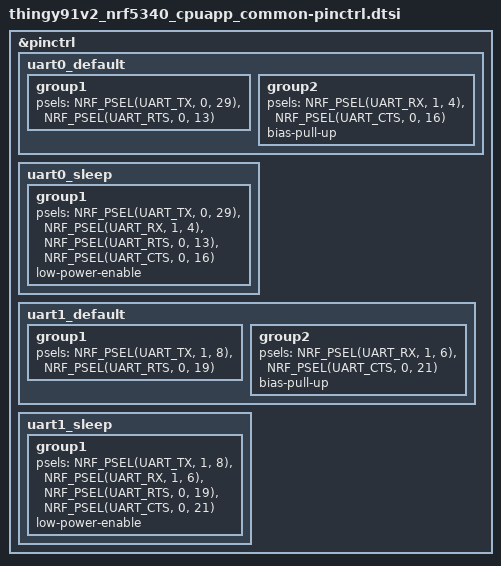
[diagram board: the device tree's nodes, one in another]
/*
 * Copyright (c) 2023 Nordic Semiconductor
 * SPDX-License-Identifier: Apache-2.0
 */

&pinctrl {
	uart0_default: uart0_default {
		group1 {
			psels = <NRF_PSEL(UART_TX, 0, 29)>,
				<NRF_PSEL(UART_RTS, 0, 13)>;
		};
		group2 {
			psels = <NRF_PSEL(UART_RX, 1, 4)>,
				<NRF_PSEL(UART_CTS, 0, 16)>;
			bias-pull-up;
		};
	};

	uart0_sleep: uart0_sleep {
		group1 {
			psels = <NRF_PSEL(UART_TX, 0, 29)>,
				<NRF_PSEL(UART_RX, 1, 4)>,
				<NRF_PSEL(UART_RTS, 0, 13)>,
				<NRF_PSEL(UART_CTS, 0, 16)>;
			low-power-enable;
		};
	};

	uart1_default: uart1_default {
		group1 {
			psels = <NRF_PSEL(UART_TX, 1, 8)>,
				<NRF_PSEL(UART_RTS, 0, 19)>;
		};
		group2 {
			psels = <NRF_PSEL(UART_RX, 1, 6)>,
				<NRF_PSEL(UART_CTS, 0, 21)>;
			bias-pull-up;
		};
	};

	uart1_sleep: uart1_sleep {
		group1 {
			psels = <NRF_PSEL(UART_TX, 1, 8)>,
				<NRF_PSEL(UART_RX, 1, 6)>,
				<NRF_PSEL(UART_RTS, 0, 19)>,
				<NRF_PSEL(UART_CTS, 0, 21)>;
			low-power-enable;
		};
	};
};
